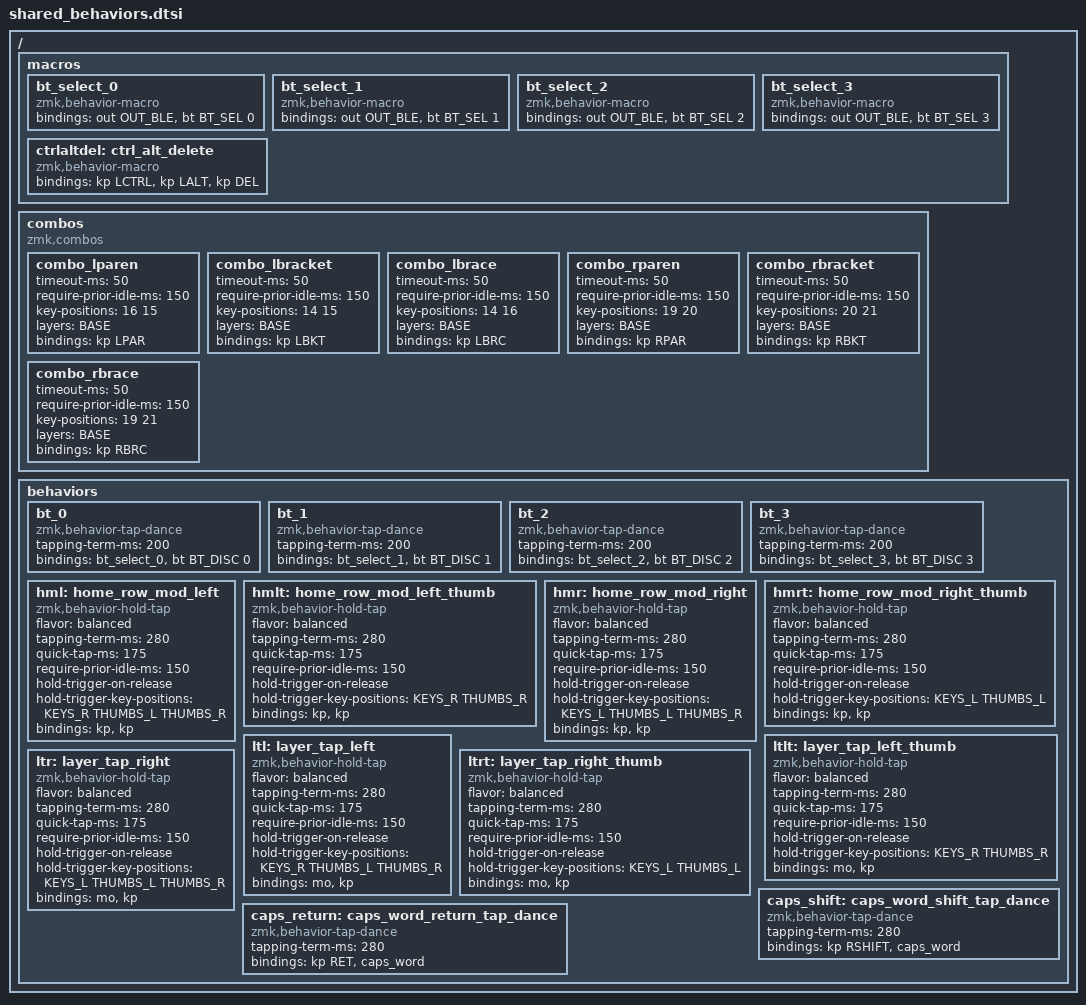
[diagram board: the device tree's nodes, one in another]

#define HYPER LC(LS(LG(LALT)))
#define MEH LC(LALT(LCTRL))
#define SUPER LG(LALT(LCTRL))

#define QUICK_TAP_MS 175

#define BASE 0
#define DEVLEFT 1
#define DEVRIGHT 2
#define NPAD 3
#define SYSTEM 4
#define MOUSE 5
#define NAV 6

/ {
    macros {
        bt_select_0: bt_select_0 {
            compatible = "zmk,behavior-macro";
            #binding-cells = <0>;
            bindings = <&out OUT_BLE>, <&bt BT_SEL 0>;
        };
        bt_select_1: bt_select_1 {
            compatible = "zmk,behavior-macro";
            #binding-cells = <0>;
            bindings = <&out OUT_BLE>, <&bt BT_SEL 1>;
        };
        bt_select_2: bt_select_2 {
            compatible = "zmk,behavior-macro";
            #binding-cells = <0>;
            bindings = <&out OUT_BLE>, <&bt BT_SEL 2>;
        };
        bt_select_3: bt_select_3 {
            compatible = "zmk,behavior-macro";
            #binding-cells = <0>;
            bindings = <&out OUT_BLE>, <&bt BT_SEL 3>;
        };
        ctrlaltdel: ctrl_alt_delete {
            compatible = "zmk,behavior-macro";
            #binding-cells = <0>;
            bindings = <&kp LCTRL>, <&kp LALT>, <&kp DEL>;
        };
    };
    combos {
        compatible = "zmk,combos";
        /*
          KEY POSITIONS
          ╭────────────────────────╮  ╭────────────────────────╮
          │ 0   1   2   3   4   5    │  │ 6   7   8   9   10  11 │
          │ 12  13  14  15  16  17   │  │ 18  19  20  21  22  23 │
          │ 24  25  26  27  28  29   │  │ 30  31  32  33  34  35 │
          ╰───────────╮ 36  37  38  │  │ 39  40  41 ╭───────────╯
                       ╰────────────╯  ╰────────────╯
        */
        combo_lparen {
            timeout-ms = <50>;
            require-prior-idle-ms = <150>;
            key-positions = <16 15>;
            layers = <BASE>;
            bindings = <&kp LPAR>;
        };
        combo_lbracket {
            timeout-ms = <50>;
            require-prior-idle-ms = <150>;
            key-positions = <14 15>;
            layers = <BASE>;
            bindings = <&kp LBKT>;
        };
        combo_lbrace {
            timeout-ms = <50>;
            require-prior-idle-ms = <150>;
            key-positions = <14 16>;
            layers = <BASE>;
            bindings = <&kp LBRC>;
        };
        combo_rparen {
            timeout-ms = <50>;
            require-prior-idle-ms = <150>;
            key-positions = <19 20>;
            layers = <BASE>;
            bindings = <&kp RPAR>;
        };
        combo_rbracket {
            timeout-ms = <50>;
            require-prior-idle-ms = <150>;
            key-positions = <20 21>;
            layers = <BASE>;
            bindings = <&kp RBKT>;
        };
        combo_rbrace {
            timeout-ms = <50>;
            require-prior-idle-ms = <150>;
            key-positions = <19 21>;
            layers = <BASE>;
            bindings = <&kp RBRC>;
        };
    };
    behaviors {
        bt_0: bt_0 {
            compatible = "zmk,behavior-tap-dance";
            #binding-cells = <0>;
            tapping-term-ms = <200>;
            bindings = <&bt_select_0>, <&bt BT_DISC 0>;
        };
        bt_1: bt_1 {
            compatible = "zmk,behavior-tap-dance";
            #binding-cells = <0>;
            tapping-term-ms = <200>;
            bindings = <&bt_select_1>, <&bt BT_DISC 1>;
        };
        bt_2: bt_2 {
            compatible = "zmk,behavior-tap-dance";
            #binding-cells = <0>;
            tapping-term-ms = <200>;
            bindings = <&bt_select_2>, <&bt BT_DISC 2>;
        };
        bt_3: bt_3 {
            compatible = "zmk,behavior-tap-dance";
            #binding-cells = <0>;
            tapping-term-ms = <200>;
            bindings = <&bt_select_3>, <&bt BT_DISC 3>;
        };

        hml: home_row_mod_left {
            compatible = "zmk,behavior-hold-tap";
            #binding-cells = <2>;
            flavor = "balanced";
            tapping-term-ms = <280>;
            quick-tap-ms = <175>;
            require-prior-idle-ms = <150>;
            hold-trigger-on-release;
            hold-trigger-key-positions = <KEYS_R THUMBS_L THUMBS_R>;
            bindings = <&kp>, <&kp>;
        };

        hmlt: home_row_mod_left_thumb {
            compatible = "zmk,behavior-hold-tap";
            #binding-cells = <2>;
            flavor = "balanced";
            tapping-term-ms = <280>;
            quick-tap-ms = <175>;
            require-prior-idle-ms = <150>;
            hold-trigger-on-release;
            hold-trigger-key-positions = <KEYS_R THUMBS_R>; // Right hand keys + right thumbs
            bindings = <&kp>, <&kp>;
        };

        hmr: home_row_mod_right {
            compatible = "zmk,behavior-hold-tap";
            #binding-cells = <2>;
            flavor = "balanced";
            tapping-term-ms = <280>;
            quick-tap-ms = <175>;
            require-prior-idle-ms = <150>;
            hold-trigger-on-release;
            hold-trigger-key-positions = <KEYS_L THUMBS_L THUMBS_R>;
            bindings = <&kp>, <&kp>;
        };

        hmrt: home_row_mod_right_thumb {
            compatible = "zmk,behavior-hold-tap";
            #binding-cells = <2>;
            flavor = "balanced";
            tapping-term-ms = <280>;
            quick-tap-ms = <175>;
            require-prior-idle-ms = <150>;
            hold-trigger-on-release;
            hold-trigger-key-positions = <KEYS_L THUMBS_L>; // Left hand keys + left thumbs
            bindings = <&kp>, <&kp>;
        };

        ltl: layer_tap_left {
            compatible = "zmk,behavior-hold-tap";
            #binding-cells = <2>;
            flavor = "balanced";
            tapping-term-ms = <280>;
            quick-tap-ms = <175>;
            require-prior-idle-ms = <150>;
            hold-trigger-on-release;
            hold-trigger-key-positions = <KEYS_R THUMBS_L THUMBS_R>;
            bindings = <&mo>, <&kp>;
        };
            
        ltlt: layer_tap_left_thumb {
            compatible = "zmk,behavior-hold-tap";
            #binding-cells = <2>;
            flavor = "balanced";
            tapping-term-ms = <280>;
            quick-tap-ms = <175>;
            require-prior-idle-ms = <150>;
            hold-trigger-on-release;
            hold-trigger-key-positions = <KEYS_R THUMBS_R>; // Right hand keys + right thumbs
            bindings = <&mo>, <&kp>;
        };

        ltr: layer_tap_right {
            compatible = "zmk,behavior-hold-tap";
            #binding-cells = <2>;
            flavor = "balanced";
            tapping-term-ms = <280>;
            quick-tap-ms = <175>;
            require-prior-idle-ms = <150>;
            hold-trigger-on-release;
            hold-trigger-key-positions = <KEYS_L THUMBS_L THUMBS_R>;
            bindings = <&mo>, <&kp>;
        };

        ltrt: layer_tap_right_thumb {
            compatible = "zmk,behavior-hold-tap";
            #binding-cells = <2>;
            flavor = "balanced";
            tapping-term-ms = <280>;
            quick-tap-ms = <175>;
            require-prior-idle-ms = <150>;
            hold-trigger-on-release;
            hold-trigger-key-positions = <KEYS_L THUMBS_L>; // Left hand keys + left thumbs
            bindings = <&mo>, <&kp>;
        };
        
        caps_shift: caps_word_shift_tap_dance {
            compatible = "zmk,behavior-tap-dance";
            #binding-cells = <0>;
            tapping-term-ms = <280>;
            bindings = <&kp RSHIFT>, <&caps_word>;
        };

        caps_return: caps_word_return_tap_dance {
            compatible = "zmk,behavior-tap-dance";
            #binding-cells = <0>;
            tapping-term-ms = <280>;
            bindings = <&kp RET>, <&caps_word>;
        };
    };
};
